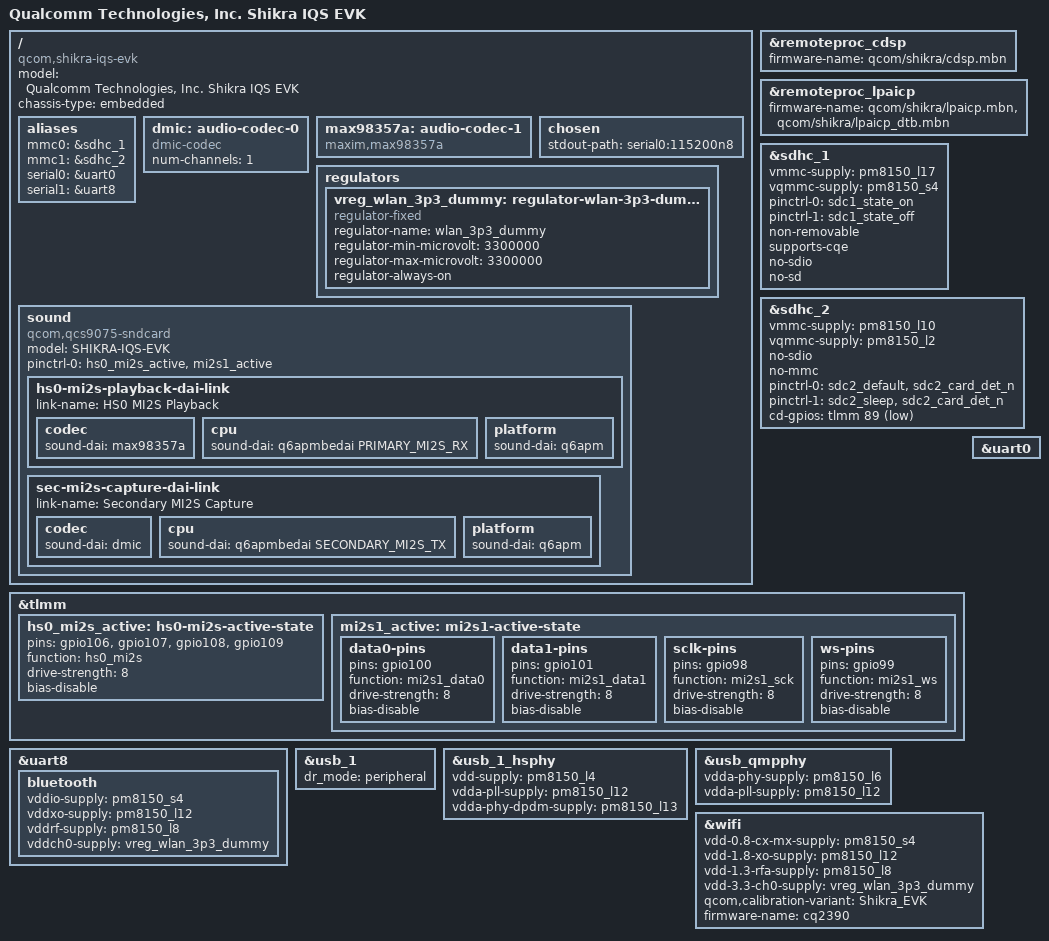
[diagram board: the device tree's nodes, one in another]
// SPDX-License-Identifier: BSD-3-Clause
/*
 * Copyright (c) Qualcomm Technologies, Inc. and/or its subsidiaries.
 */

/dts-v1/;

#include "shikra-iqs-som.dtsi"
#include "shikra-evk.dtsi"
#include <dt-bindings/gpio/gpio.h>
#include <dt-bindings/sound/qcom,q6afe.h>

/ {
	model = "Qualcomm Technologies, Inc. Shikra IQS EVK";
	compatible = "qcom,shikra-iqs-evk", "qcom,shikra-iqs-som", "qcom,shikra";
	chassis-type = "embedded";

	aliases {
		mmc0 = &sdhc_1;
		mmc1 = &sdhc_2; /* SDC2 SD card slot */
		serial0 = &uart0;
		serial1 = &uart8;
	};

	dmic: audio-codec-0 {
		compatible = "dmic-codec";
		#sound-dai-cells = <0>;
		num-channels = <1>;
	};

	max98357a: audio-codec-1 {
		compatible = "maxim,max98357a";
		#sound-dai-cells = <0>;
	};

	chosen {
		stdout-path = "serial0:115200n8";
	};

	regulators {
		vreg_wlan_3p3_dummy: regulator-wlan-3p3-dummy {
			compatible = "regulator-fixed";
			regulator-name = "wlan_3p3_dummy";
			regulator-min-microvolt = <3300000>;
			regulator-max-microvolt = <3300000>;
			regulator-always-on;
		};
	};

	sound {
		compatible = "qcom,qcs9075-sndcard";
		model = "SHIKRA-IQS-EVK";
		status = "okay";

		pinctrl-0 = <&hs0_mi2s_active>, <&mi2s1_active>;
		pinctrl-names = "default";

		hs0-mi2s-playback-dai-link {
			link-name = "HS0 MI2S Playback";

			codec {
				sound-dai = <&max98357a>;
			};

			cpu {
				sound-dai = <&q6apmbedai PRIMARY_MI2S_RX>;
			};

			platform {
				sound-dai = <&q6apm>;
			};
		};

		sec-mi2s-capture-dai-link {
			link-name = "Secondary MI2S Capture";

			codec {
				sound-dai = <&dmic>;
			};

			cpu {
				sound-dai = <&q6apmbedai SECONDARY_MI2S_TX>;
			};

			platform {
				sound-dai = <&q6apm>;
			};
		};
	};

};

&remoteproc_cdsp {
	firmware-name = "qcom/shikra/cdsp.mbn";

	status = "okay";
};

&remoteproc_lpaicp {
	firmware-name = "qcom/shikra/lpaicp.mbn",
			"qcom/shikra/lpaicp_dtb.mbn";

	status = "okay";
};

&sdhc_1 {
	vmmc-supply = <&pm8150_l17>;
	vqmmc-supply = <&pm8150_s4>;

	pinctrl-0 = <&sdc1_state_on>;
	pinctrl-1 = <&sdc1_state_off>;
	pinctrl-names = "default", "sleep";

	non-removable;
	supports-cqe;
	no-sdio;
	no-sd;

	status = "okay";
};

&sdhc_2 {
	vmmc-supply = <&pm8150_l10>;
	vqmmc-supply = <&pm8150_l2>;

	no-sdio;
	no-mmc;

	pinctrl-0 = <&sdc2_default &sdc2_card_det_n>;
	pinctrl-1 = <&sdc2_sleep &sdc2_card_det_n>;
	pinctrl-names = "default", "sleep";

	cd-gpios = <&tlmm 89 GPIO_ACTIVE_LOW>;

	status = "okay";
};

&tlmm {
	hs0_mi2s_active: hs0-mi2s-active-state {
		pins = "gpio106", "gpio107", "gpio108", "gpio109";
		function = "hs0_mi2s";
		drive-strength = <8>;
		bias-disable;
	};

	mi2s1_active: mi2s1-active-state {
		data0-pins {
			pins = "gpio100";
			function = "mi2s1_data0";
			drive-strength = <8>;
			bias-disable;
		};

		data1-pins {
			pins = "gpio101";
			function = "mi2s1_data1";
			drive-strength = <8>;
			bias-disable;
		};

		sclk-pins {
			pins = "gpio98";
			function = "mi2s1_sck";
			drive-strength = <8>;
			bias-disable;
		};

		ws-pins {
			pins = "gpio99";
			function = "mi2s1_ws";
			drive-strength = <8>;
			bias-disable;
		};
	};
};

&uart0 {
	status = "okay";
};

&uart8 {
	status = "okay";

	bluetooth {
		vddio-supply = <&pm8150_s4>;
		vddxo-supply = <&pm8150_l12>;
		vddrf-supply = <&pm8150_l8>;
		vddch0-supply = <&vreg_wlan_3p3_dummy>;
	};
};

&usb_1 {
	dr_mode = "peripheral";

	status = "okay";
};

&usb_1_hsphy {
	vdd-supply = <&pm8150_l4>;
	vdda-pll-supply = <&pm8150_l12>;
	vdda-phy-dpdm-supply = <&pm8150_l13>;

	status = "okay";
};

&usb_qmpphy {
	vdda-phy-supply = <&pm8150_l6>;
	vdda-pll-supply = <&pm8150_l12>;

	status = "okay";
};

&wifi {
	vdd-0.8-cx-mx-supply = <&pm8150_s4>;
	vdd-1.8-xo-supply = <&pm8150_l12>;
	vdd-1.3-rfa-supply = <&pm8150_l8>;
	vdd-3.3-ch0-supply = <&vreg_wlan_3p3_dummy>;
	qcom,calibration-variant = "Shikra_EVK";
	firmware-name = "cq2390";

	status = "okay";
};
